# MCXN947_cm33_core0 register map
Vendor: nxp.com; File version: 1.0
CPU: CM33 r2p0, little endian, MPU, FPU, VTOR, 3 interrupt priority bits
Registers are 32-bit, read-write, reset 0x0 unless marked. A register's access mark holds for its fields unless they carry their own. Offsets are from the block's base; [hi:lo] are bit positions; {n}, {i} and the like mark numbered series.

## LPTMR0 — LPTMR
Base 0x4004A000
Same registers: LPTMR1 0x4004B000
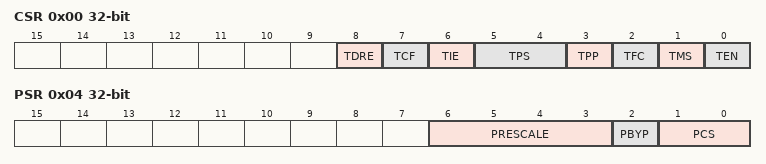
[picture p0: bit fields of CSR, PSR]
0x00 CSR — Control Status
  [8] TDRE — Timer DMA Request Enable
    0=trde0 (Disable); 1=trde1 (Enable)
  [7] TCF write-1-clears — Timer Compare Flag
    0=CNR != (CMR + 1); 1=CNR = (CMR + 1)
  [6] TIE — Timer Interrupt Enable
    0=Disable; 1=Enable
  [5:4] TPS — Timer Pin Select
    {v}=Input {v} (v=0..3)
  [3] TPP — Timer Pin Polarity
    0=Active-high; 1=Active-low
  [2] TFC — Timer Free-Running Counter
    0=Reset if TCF set; 1=Reset on overflow
  [1] TMS — Timer Mode Select
    0=Time Counter mode; 1=Pulse Counter mode
  [0] TEN — Timer Enable
    0=Disable; 1=Enable
0x04 PSR — Prescale and Glitch Filter
  [6:3] PRESCALE — Prescale/Glitch Filter Value
    0=Prescaler divides the prescaler clock by 2; glitch filter does not support this configuration; 1=Prescaler divides the prescaler clock by 4; glitch filter recognizes change on input pin after 2 rising clock edges; 2=Prescaler divides the prescaler clock by 8; glitch filter recognizes change on input pin after 4 rising clock edges; 3=Prescaler divides the prescaler clock by 16; glitch filter recognizes change on input pin after 8 rising clock edges; 4=Prescaler divides the prescaler clock by 32; glitch filter recognizes change on input pin after 16 rising clock edges; 5=Prescaler divides the prescaler clock by 64; glitch filter recognizes change on input pin after 32 rising clock edges; 6=Prescaler divides the prescaler clock by 128; glitch filter recognizes change on input pin after 64 rising clock edges; 7=Prescaler divides the prescaler clock by 256; glitch filter recognizes change on input pin after 128 rising clock edges; 8=Prescaler divides the prescaler clock by 512; glitch filter recognizes change on input pin after 256 rising clock edges; 9=Prescaler divides the prescaler clock by 1024; glitch filter recognizes change on input pin after 512 rising clock edges; 10=Prescaler divides the prescaler clock by 2048; glitch filter recognizes change on input pin after 1024 rising clock edges; 11=Prescaler divides the prescaler clock by 4096; glitch filter recognizes change on input pin after 2048 rising clock edges; 12=Prescaler divides the prescaler clock by 8192; glitch filter recognizes change on input pin after 4096 rising clock edges; 13=Prescaler divides the prescaler clock by 16,384; glitch filter recognizes change on input pin after 8192 rising clock edges; 14=Prescaler divides the prescaler clock by 32,768; glitch filter recognizes change on input pin after 16,384 rising clock edges; 15=Prescaler divides the prescaler clock by 65,536; glitch filter recognizes change on input pin after 32,768 rising clock edges
  [2] PBYP — Prescaler/Glitch Filter Bypass
    0=Prescaler/glitch filter enable; 1=Prescaler/glitch filter bypass
  [1:0] PCS — Prescaler/Glitch Filter Clock Select
    {v}=Clock {v} (v=0..3)
0x08 CMR — Compare
  [31:0] COMPARE — Compare Value
0x0C CNR — Counter
  [31:0] COUNTER — Counter Value

## RTC_SUBSYSTEM0 — RTC_SUBSYSTEM
Base 0x4004C000; alternate view of RTC0
0x800 SUBSECOND_CTRL — Subsecond Control
  [0] SUB_SECOND_CNT_EN — Subsecond Counter Enable
    0=DISABLE (Disabled); 1=ENABLE (Enabled)
0x804 SUBSECOND_CNT ro — Subsecond Counter
  [15:0] SUBSECOND_CNT — Current Subsecond Counter Value
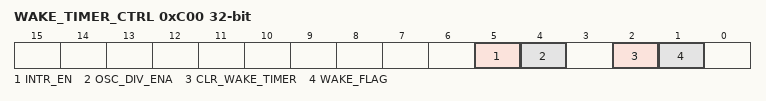
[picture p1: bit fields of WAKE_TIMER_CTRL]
0xC00 WAKE_TIMER_CTRL — Wake Timer Control
  [5] INTR_EN — Enable Interrupt
    0=DISABLE (Disabled); 1=ENABLE (Enabled)
  [4] OSC_DIV_ENA — OSC Divide Enable
    0=DISABLE (Disabled); 1=ENABLE (Enabled)
  [2] CLR_WAKE_TIMER wo — Clear Wake Timer
    0=DISABLE (No effect.); 1=ENABLE (Clears the wake timer counter and halts operation until a new count value is loaded.)
  [1] WAKE_FLAG write-1-clears — Wake Timer Status Flag
    0=DISABLE (Wake timer has not timed out.); 1=ENABLE (Wake timer has timed out.)
0xC0C WAKE_TIMER_CNT — Wake Timer Counter
  [31:0] WAKE_CNT — Wake Counter
